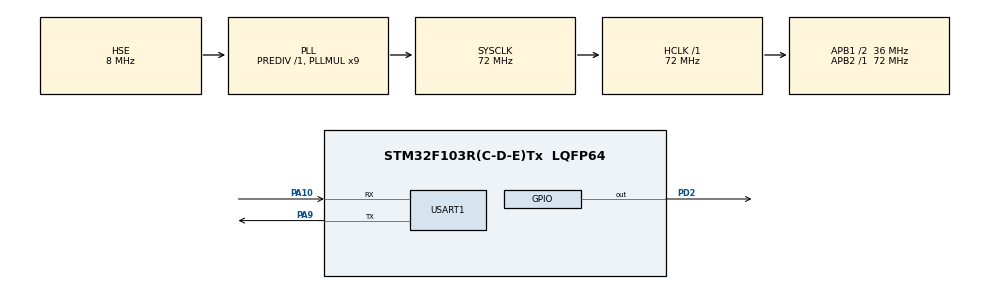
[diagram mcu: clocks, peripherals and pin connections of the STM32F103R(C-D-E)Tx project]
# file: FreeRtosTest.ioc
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FREERTOS.Tasks01=defaultTask,24,128,StartDefaultTask,Default,NULL,Dynamic,NULL,NULL;LED,8,128,StartTask02,Default,NULL,Dynamic,NULL,NULL;UART,8,128,StartTask03,Default,NULL,Dynamic,NULL,NULL
Mcu.Family=STM32F1
Mcu.Name=STM32F103R(C-D-E)Tx
Mcu.Package=LQFP64
NVIC.PriorityGroup=NVIC_PRIORITYGROUP_4
PA10.Mode=Asynchronous
PA10.Signal=USART1_RX
PA13.Mode=Serial_Wire
PA13.Signal=SYS_JTMS-SWDIO
PA14.Mode=Serial_Wire
PA14.Signal=SYS_JTCK-SWCLK
PA9.Mode=Asynchronous
PA9.Signal=USART1_TX
PD0-OSC_IN.Mode=HSE-External-Oscillator
PD0-OSC_IN.Signal=RCC_OSC_IN
PD1-OSC_OUT.Mode=HSE-External-Oscillator
PD1-OSC_OUT.Signal=RCC_OSC_OUT
PD2.Signal=GPIO_Output
ProjectManager.HeapSize=0x200
ProjectManager.StackSize=0x400
ProjectManager.TargetToolchain=SW4STM32
RCC.AHBFreq_Value=72000000
RCC.APB1CLKDivider=RCC_HCLK_DIV2
RCC.APB1Freq_Value=36000000
RCC.APB1TimFreq_Value=72000000
RCC.APB2Freq_Value=72000000
RCC.APB2TimFreq_Value=72000000
RCC.HCLKFreq_Value=72000000
RCC.PLLMUL=RCC_PLL_MUL9
RCC.PLLSourceVirtual=RCC_PLLSOURCE_HSE
RCC.SYSCLKFreq_VALUE=72000000
RCC.SYSCLKSource=RCC_SYSCLKSOURCE_PLLCLK
RCC.USBFreq_Value=72000000
USART1.VirtualMode=VM_ASYNC
VP_FREERTOS_VS_CMSIS_V2.Mode=CMSIS_V2
board=custom

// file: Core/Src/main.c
/* USER CODE BEGIN Header */
/**
  ******************************************************************************
  * @file           : main.c
  * @brief          : Main program body
  ******************************************************************************
  * @attention
  *
  * <h2><center>&copy; Copyright (c) 2023 STMicroelectronics.
  * All rights reserved.</center></h2>
  *
  * This software component is licensed by ST under Ultimate Liberty license
  * SLA0044, the "License"; You may not use this file except in compliance with
  * the License. You may obtain a copy of the License at:
  *                             www.st.com/SLA0044
  *
  ******************************************************************************
  */
/* USER CODE END Header */
#include "main.h"
#include "cmsis_os.h"
#include "usart.h"
#include "gpio.h"

void SystemClock_Config(void);
void MX_FREERTOS_Init(void);

int main(void)
{

  /* MCU Configuration--------------------------------------------------------*/

  /* Reset of all peripherals, Initializes the Flash interface and the Systick. */
  HAL_Init();

  /* USER CODE BEGIN Init */
    RetargetInit(&huart1);
  /* USER CODE END Init */

  /* Configure the system clock */
  SystemClock_Config();

  /* Initialize all configured peripherals */
  MX_GPIO_Init();
  MX_USART1_UART_Init();

  /* Init scheduler */
  osKernelInitialize();  /* Call init function for freertos objects (in freertos.c) */
  MX_FREERTOS_Init();
  /* Start scheduler */
  osKernelStart();

  /* We should never get here as control is now taken by the scheduler */
  /* Infinite loop */
  while (1)
  {

  }
}

void SystemClock_Config(void)
{
  RCC_OscInitTypeDef RCC_OscInitStruct = {0};
  RCC_ClkInitTypeDef RCC_ClkInitStruct = {0};

  /** Initializes the RCC Oscillators according to the specified parameters
  * in the RCC_OscInitTypeDef structure.
  */
  RCC_OscInitStruct.OscillatorType = RCC_OSCILLATORTYPE_HSE;
  RCC_OscInitStruct.HSEState = RCC_HSE_ON;
  RCC_OscInitStruct.HSEPredivValue = RCC_HSE_PREDIV_DIV1;
  RCC_OscInitStruct.HSIState = RCC_HSI_ON;
  RCC_OscInitStruct.PLL.PLLState = RCC_PLL_ON;
  RCC_OscInitStruct.PLL.PLLSource = RCC_PLLSOURCE_HSE;
  RCC_OscInitStruct.PLL.PLLMUL = RCC_PLL_MUL9;
  if (HAL_RCC_OscConfig(&RCC_OscInitStruct) != HAL_OK)
  {
    Error_Handler();
  }
  /** Initializes the CPU, AHB and APB buses clocks
  */
  RCC_ClkInitStruct.ClockType = RCC_CLOCKTYPE_HCLK|RCC_CLOCKTYPE_SYSCLK
                              |RCC_CLOCKTYPE_PCLK1|RCC_CLOCKTYPE_PCLK2;
  RCC_ClkInitStruct.SYSCLKSource = RCC_SYSCLKSOURCE_PLLCLK;
  RCC_ClkInitStruct.AHBCLKDivider = RCC_SYSCLK_DIV1;
  RCC_ClkInitStruct.APB1CLKDivider = RCC_HCLK_DIV2;
  RCC_ClkInitStruct.APB2CLKDivider = RCC_HCLK_DIV1;

  if (HAL_RCC_ClockConfig(&RCC_ClkInitStruct, FLASH_LATENCY_2) != HAL_OK)
  {
    Error_Handler();
  }
}

void Error_Handler(void)
{
  __disable_irq();
  while (1)
  {
  }
}

/************************ (C) COPYRIGHT STMicroelectronics *****END OF FILE****/

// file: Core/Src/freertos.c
/* USER CODE BEGIN Header */
/**
  ******************************************************************************
  * File Name          : freertos.c
  * Description        : Code for freertos applications
  ******************************************************************************
  * @attention
  *
  * <h2><center>&copy; Copyright (c) 2023 STMicroelectronics.
  * All rights reserved.</center></h2>
  *
  * This software component is licensed by ST under Ultimate Liberty license
  * SLA0044, the "License"; You may not use this file except in compliance with
  * the License. You may obtain a copy of the License at:
  *                             www.st.com/SLA0044
  *
  ******************************************************************************
  */
/* USER CODE END Header */

#include "FreeRTOS.h"
#include "task.h"
#include "main.h"
#include "cmsis_os.h"

/* Definitions for defaultTask */
osThreadId_t defaultTaskHandle;
const osThreadAttr_t defaultTask_attributes = {
  .name = "defaultTask",
  .stack_size = 128 * 4,
  .priority = (osPriority_t) osPriorityNormal,
};
/* Definitions for LED */
osThreadId_t LEDHandle;
const osThreadAttr_t LED_attributes = {
  .name = "LED",
  .stack_size = 128 * 4,
  .priority = (osPriority_t) osPriorityLow,
};
/* Definitions for UART */
osThreadId_t UARTHandle;
const osThreadAttr_t UART_attributes = {
  .name = "UART",
  .stack_size = 128 * 4,
  .priority = (osPriority_t) osPriorityLow,
};

void StartDefaultTask(void *argument);
void StartTask02(void *argument);
void StartTask03(void *argument);

void MX_FREERTOS_Init(void); /* (MISRA C 2004 rule 8.1) */

void MX_FREERTOS_Init(void) {

  /* Create the thread(s) */
  /* creation of defaultTask */
  defaultTaskHandle = osThreadNew(StartDefaultTask, NULL, &defaultTask_attributes);

  /* creation of LED */
  LEDHandle = osThreadNew(StartTask02, NULL, &LED_attributes);

  /* creation of UART */
  UARTHandle = osThreadNew(StartTask03, NULL, &UART_attributes);

}

void StartDefaultTask(void *argument)
{
  for(;;)
  {
    osDelay(1);
  }
}

void StartTask02(void *argument)
{
  /* USER CODE BEGIN StartTask02 */
  /* Infinite loop */
  for(;;)
  {
      HAL_GPIO_TogglePin(GPIOD, GPIO_PIN_2);
      HAL_Delay(1000);
    osDelay(1);
  }
  /* USER CODE END StartTask02 */
}

void StartTask03(void *argument)
{
  /* USER CODE BEGIN StartTask03 */
  /* Infinite loop */
  for(;;)
  {
      printf("hello freertos\r\n");
      HAL_Delay(1000);
    osDelay(1);
  }
  /* USER CODE END StartTask03 */
}

/************************ (C) COPYRIGHT STMicroelectronics *****END OF FILE****/
